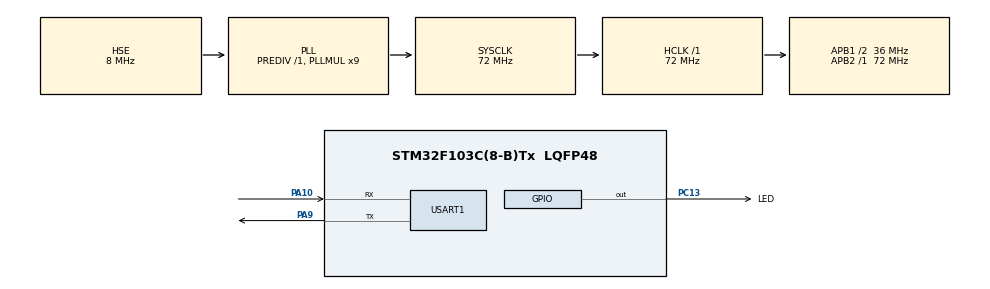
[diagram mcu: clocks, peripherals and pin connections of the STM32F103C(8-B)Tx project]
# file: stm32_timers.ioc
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Mcu.Family=STM32F1
Mcu.Name=STM32F103C(8-B)Tx
Mcu.Package=LQFP48
NVIC.PriorityGroup=NVIC_PRIORITYGROUP_4
NVIC.TIM2_IRQn=true\:0\:0\:false\:false\:true\:true\:true
PA10.Mode=Asynchronous
PA10.Signal=USART1_RX
PA13.Mode=Serial_Wire
PA13.Signal=SYS_JTMS-SWDIO
PA14.Mode=Serial_Wire
PA14.Signal=SYS_JTCK-SWCLK
PA9.Mode=Asynchronous
PA9.Signal=USART1_TX
PC13-TAMPER-RTC.GPIO_Label=LED
PC13-TAMPER-RTC.Signal=GPIO_Output
PD0-OSC_IN.Mode=HSE-External-Oscillator
PD0-OSC_IN.Signal=RCC_OSC_IN
PD1-OSC_OUT.Mode=HSE-External-Oscillator
PD1-OSC_OUT.Signal=RCC_OSC_OUT
ProjectManager.HeapSize=0x200
ProjectManager.StackSize=0x400
ProjectManager.TargetToolchain=STM32CubeIDE
RCC.AHBFreq_Value=72000000
RCC.APB1CLKDivider=RCC_HCLK_DIV2
RCC.APB1Freq_Value=36000000
RCC.APB1TimFreq_Value=72000000
RCC.APB2Freq_Value=72000000
RCC.APB2TimFreq_Value=72000000
RCC.HCLKFreq_Value=72000000
RCC.PLLMUL=RCC_PLL_MUL9
RCC.PLLSourceVirtual=RCC_PLLSOURCE_HSE
RCC.SYSCLKFreq_VALUE=72000000
RCC.SYSCLKSource=RCC_SYSCLKSOURCE_PLLCLK
RCC.USBFreq_Value=72000000
TIM2.Period=10000-1
TIM2.Prescaler=7200-1
USART1.VirtualMode=VM_ASYNC
VP_TIM2_VS_ClockSourceINT.Mode=Internal
board=custom

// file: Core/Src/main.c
/* USER CODE BEGIN Header */
/**
  ******************************************************************************
  * @file           : main.c
  * @brief          : Main program body
  ******************************************************************************
  * @attention
  *
  * <h2><center>&copy; Copyright (c) 2021 STMicroelectronics.
  * All rights reserved.</center></h2>
  *
  * This software component is licensed by ST under BSD 3-Clause license,
  * the "License"; You may not use this file except in compliance with the
  * License. You may obtain a copy of the License at:
  *                        opensource.org/licenses/BSD-3-Clause
  *
  ******************************************************************************
  */
/* USER CODE END Header */
#include "main.h"

/* USER CODE BEGIN Includes */

// Incluyo la standard io por que quiero usar sprintf
#include"stdio.h"

/* USER CODE END Includes */

TIM_HandleTypeDef htim2;

UART_HandleTypeDef huart1;

void SystemClock_Config(void);
static void MX_GPIO_Init(void);
static void MX_USART1_UART_Init(void);
static void MX_TIM2_Init(void);

int main(void)
{
  /* USER CODE BEGIN 1 */
  char uart_buffer[32];
  int uart_length;
  uint16_t timer_val;
  /* USER CODE END 1 */

  /* MCU Configuration--------------------------------------------------------*/

  /* Reset of all peripherals, Initializes the Flash interface and the Systick. */
  HAL_Init();

  /* Configure the system clock */
  SystemClock_Config();

  /* Initialize all configured peripherals */
  MX_GPIO_Init();
  MX_USART1_UART_Init();
  MX_TIM2_Init();
  /* USER CODE BEGIN 2 */

  // Escribo algo en la uart 1
  uart_length = sprintf(uart_buffer,"Timer test \r\n");
  HAL_UART_Transmit(&huart1, (uint8_t *)uart_buffer, uart_length, HAL_MAX_DELAY);

  // Inicio el Timer2
//  HAL_TIM_Base_Start(&htim2);
  HAL_TIM_Base_Start_IT(&htim2);

  // Miro el valor del Timer 2
  timer_val = __HAL_TIM_GET_COUNTER(&htim2); //h de htim2 significa HANDLER

  /* USER CODE END 2 */

  /* Infinite loop */
  /* USER CODE BEGIN WHILE */
  while (1)
  {
	// Tengo el clock a 72 Mhz, con los prescalers (71) cuento a 1 Mhz entonces
	// el Timer 2 va a desbordar cada 65535 uSeg o 65.535 mSeg por esto para calibrar espero
	// un tiempo menor al que desborda
	// HAL_Delay(50);// Al parecer, HAL_Delay tarda 1 mSeg mas de lo que se le pide

	// Ahora si el prescaler lo cambio a 7200-1 el Timer 2 va a contar a una frecuencia de
	// 10kHz por lo que contar 65535 le lleva 6.55 Segundos

	// Procedo a generar un delay asincrono de 1 segundo

	/* if(__HAL_TIM_GET_COUNTER(&htim2) - timer_val >= 10000)
	{
		// Cambio el estadod el LED cada 1 segundo
		HAL_GPIO_TogglePin(LED_GPIO_Port, LED_Pin);

		// Escribo en la uart1 la cantidad de taps del timer
		uart_length = sprintf(uart_buffer,"%u\r\n",timer_val);
		HAL_UART_Transmit(&huart1, (uint8_t *)uart_buffer, uart_length, HAL_MAX_DELAY);

		//Actualizo el valor del timer
	    timer_val = __HAL_TIM_GET_COUNTER(&htim2);
	}*/

    /* USER CODE END WHILE */

  }
}

void SystemClock_Config(void)
{
  RCC_OscInitTypeDef RCC_OscInitStruct = {0};
  RCC_ClkInitTypeDef RCC_ClkInitStruct = {0};

  /** Initializes the RCC Oscillators according to the specified parameters
  * in the RCC_OscInitTypeDef structure.
  */
  RCC_OscInitStruct.OscillatorType = RCC_OSCILLATORTYPE_HSE;
  RCC_OscInitStruct.HSEState = RCC_HSE_ON;
  RCC_OscInitStruct.HSEPredivValue = RCC_HSE_PREDIV_DIV1;
  RCC_OscInitStruct.HSIState = RCC_HSI_ON;
  RCC_OscInitStruct.PLL.PLLState = RCC_PLL_ON;
  RCC_OscInitStruct.PLL.PLLSource = RCC_PLLSOURCE_HSE;
  RCC_OscInitStruct.PLL.PLLMUL = RCC_PLL_MUL9;
  if (HAL_RCC_OscConfig(&RCC_OscInitStruct) != HAL_OK)
  {
    Error_Handler();
  }
  /** Initializes the CPU, AHB and APB buses clocks
  */
  RCC_ClkInitStruct.ClockType = RCC_CLOCKTYPE_HCLK|RCC_CLOCKTYPE_SYSCLK
                              |RCC_CLOCKTYPE_PCLK1|RCC_CLOCKTYPE_PCLK2;
  RCC_ClkInitStruct.SYSCLKSource = RCC_SYSCLKSOURCE_PLLCLK;
  RCC_ClkInitStruct.AHBCLKDivider = RCC_SYSCLK_DIV1;
  RCC_ClkInitStruct.APB1CLKDivider = RCC_HCLK_DIV2;
  RCC_ClkInitStruct.APB2CLKDivider = RCC_HCLK_DIV1;

  if (HAL_RCC_ClockConfig(&RCC_ClkInitStruct, FLASH_LATENCY_2) != HAL_OK)
  {
    Error_Handler();
  }
}

static void MX_TIM2_Init(void)
{

  TIM_ClockConfigTypeDef sClockSourceConfig = {0};
  TIM_MasterConfigTypeDef sMasterConfig = {0};

  htim2.Instance = TIM2;
  htim2.Init.Prescaler = 7200-1;
  htim2.Init.CounterMode = TIM_COUNTERMODE_UP;
  htim2.Init.Period = 10000-1;
  htim2.Init.ClockDivision = TIM_CLOCKDIVISION_DIV1;
  htim2.Init.AutoReloadPreload = TIM_AUTORELOAD_PRELOAD_DISABLE;
  if (HAL_TIM_Base_Init(&htim2) != HAL_OK)
  {
    Error_Handler();
  }
  sClockSourceConfig.ClockSource = TIM_CLOCKSOURCE_INTERNAL;
  if (HAL_TIM_ConfigClockSource(&htim2, &sClockSourceConfig) != HAL_OK)
  {
    Error_Handler();
  }
  sMasterConfig.MasterOutputTrigger = TIM_TRGO_RESET;
  sMasterConfig.MasterSlaveMode = TIM_MASTERSLAVEMODE_DISABLE;
  if (HAL_TIMEx_MasterConfigSynchronization(&htim2, &sMasterConfig) != HAL_OK)
  {
    Error_Handler();
  }

}

static void MX_USART1_UART_Init(void)
{

  huart1.Instance = USART1;
  huart1.Init.BaudRate = 115200;
  huart1.Init.WordLength = UART_WORDLENGTH_8B;
  huart1.Init.StopBits = UART_STOPBITS_1;
  huart1.Init.Parity = UART_PARITY_NONE;
  huart1.Init.Mode = UART_MODE_TX_RX;
  huart1.Init.HwFlowCtl = UART_HWCONTROL_NONE;
  huart1.Init.OverSampling = UART_OVERSAMPLING_16;
  if (HAL_UART_Init(&huart1) != HAL_OK)
  {
    Error_Handler();
  }

}

static void MX_GPIO_Init(void)
{
  GPIO_InitTypeDef GPIO_InitStruct = {0};

  /* GPIO Ports Clock Enable */
  __HAL_RCC_GPIOC_CLK_ENABLE();
  __HAL_RCC_GPIOD_CLK_ENABLE();
  __HAL_RCC_GPIOA_CLK_ENABLE();

  /*Configure GPIO pin Output Level */
  HAL_GPIO_WritePin(LED_GPIO_Port, LED_Pin, GPIO_PIN_RESET);

  /*Configure GPIO pin : LED_Pin */
  GPIO_InitStruct.Pin = LED_Pin;
  GPIO_InitStruct.Mode = GPIO_MODE_OUTPUT_PP;
  GPIO_InitStruct.Pull = GPIO_NOPULL;
  GPIO_InitStruct.Speed = GPIO_SPEED_FREQ_LOW;
  HAL_GPIO_Init(LED_GPIO_Port, &GPIO_InitStruct);

}

/* USER CODE BEGIN 4 */

//INTERRUPCIONES:

//CallBack: Desborde de Timer 2
void HAL_TIM_PeriodElapsedCallback (TIM_HandleTypeDef * htim)
{
	// Chequeo que timer causo la interrupcion:
	if(htim == &htim2)
	{
		HAL_GPIO_TogglePin(LED_GPIO_Port, LED_Pin);
	}
}

/* USER CODE END 4 */

void Error_Handler(void)
{
  __disable_irq();
  while (1)
  {
  }
}

/************************ (C) COPYRIGHT STMicroelectronics *****END OF FILE****/
